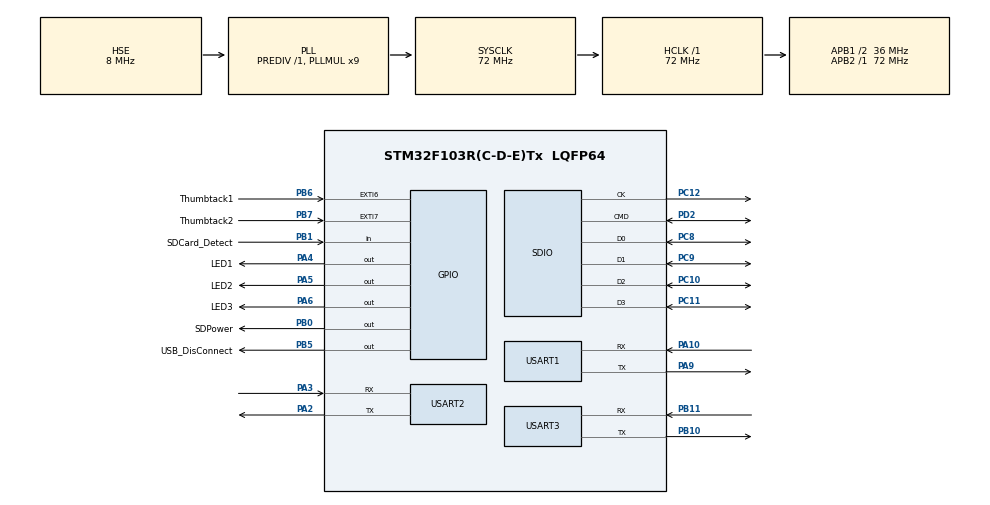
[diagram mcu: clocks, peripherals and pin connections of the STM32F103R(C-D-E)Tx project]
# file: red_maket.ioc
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FATFS._FS_NORTC=0
FATFS._STRF_ENCODE=0
FATFS._USE_MKFS=0
Mcu.Family=STM32F1
Mcu.Name=STM32F103R(C-D-E)Tx
Mcu.Package=LQFP64
NVIC.EXTI9_5_IRQn=true\:0\:0\:false\:false\:true\:true\:true\:true
NVIC.PriorityGroup=NVIC_PRIORITYGROUP_4
NVIC.USART1_IRQn=true\:0\:0\:false\:false\:true\:true\:true\:true
NVIC.USART2_IRQn=true\:0\:0\:false\:false\:true\:true\:true\:true
NVIC.USART3_IRQn=true\:0\:0\:false\:false\:true\:true\:true\:true
PA10.Mode=Asynchronous
PA10.Signal=USART1_RX
PA13.Mode=Trace_Asynchronous_SW
PA13.Signal=SYS_JTMS-SWDIO
PA14.Mode=Trace_Asynchronous_SW
PA14.Signal=SYS_JTCK-SWCLK
PA2.Mode=Asynchronous
PA2.Signal=USART2_TX
PA3.Mode=Asynchronous
PA3.Signal=USART2_RX
PA4.GPIO_Label=LED1
PA4.Signal=GPIO_Output
PA5.GPIO_Label=LED2
PA5.Signal=GPIO_Output
PA6.GPIO_Label=LED3
PA6.Signal=GPIO_Output
PA9.Mode=Asynchronous
PA9.Signal=USART1_TX
PB0.GPIO_Label=SDPower
PB0.Signal=GPIO_Output
PB1.GPIO_Label=SDCard_Detect
PB1.Signal=GPIO_Input
PB10.Mode=Asynchronous
PB10.Signal=USART3_TX
PB11.Mode=Asynchronous
PB11.Signal=USART3_RX
PB3.Mode=Trace_Asynchronous_SW
PB3.Signal=SYS_JTDO-TRACESWO
PB5.GPIO_Label=USB_DisConnect
PB5.Signal=GPIO_Output
PB6.GPIO_Label=Thumbtack1
PB6.Signal=GPXTI6
PB7.GPIO_Label=Thumbtack2
PB7.Signal=GPXTI7
PC10.Mode=SD_4_bits_Wide_bus
PC10.Signal=SDIO_D2
PC11.Mode=SD_4_bits_Wide_bus
PC11.Signal=SDIO_D3
PC12.Mode=SD_4_bits_Wide_bus
PC12.Signal=SDIO_CK
PC14-OSC32_IN.Mode=LSE-External-Oscillator
PC14-OSC32_IN.Signal=RCC_OSC32_IN
PC15-OSC32_OUT.Mode=LSE-External-Oscillator
PC15-OSC32_OUT.Signal=RCC_OSC32_OUT
PC8.Mode=SD_4_bits_Wide_bus
PC8.Signal=SDIO_D0
PC9.Mode=SD_4_bits_Wide_bus
PC9.Signal=SDIO_D1
PD0-OSC_IN.Mode=HSE-External-Oscillator
PD0-OSC_IN.Signal=RCC_OSC_IN
PD1-OSC_OUT.Mode=HSE-External-Oscillator
PD1-OSC_OUT.Signal=RCC_OSC_OUT
PD2.Mode=SD_4_bits_Wide_bus
PD2.Signal=SDIO_CMD
ProjectManager.HeapSize=0x200
ProjectManager.StackSize=0x400
ProjectManager.TargetToolchain=EWARM V8.32
RCC.AHBFreq_Value=72000000
RCC.APB1CLKDivider=RCC_HCLK_DIV2
RCC.APB1Freq_Value=36000000
RCC.APB1TimFreq_Value=72000000
RCC.APB2Freq_Value=72000000
RCC.APB2TimFreq_Value=72000000
RCC.EnbaleCSS=true
RCC.HCLKFreq_Value=72000000
RCC.PLLMUL=RCC_PLL_MUL9
RCC.PLLSourceVirtual=RCC_PLLSOURCE_HSE
RCC.RTCClockSelection=RCC_RTCCLKSOURCE_LSE
RCC.SYSCLKFreq_VALUE=72000000
RCC.SYSCLKSource=RCC_SYSCLKSOURCE_PLLCLK
RCC.USBFreq_Value=48000000
RCC.USBPrescaler=RCC_USBCLKSOURCE_PLL_DIV1_5
RTC.Date=1
RTC.Format=RTC_FORMAT_BIN
RTC.Month=RTC_MONTH_DECEMBER
RTC.WeekDay=RTC_WEEKDAY_MONDAY
RTC.Year=19
USART1.Parity=PARITY_EVEN
USART1.VirtualMode=VM_ASYNC
USART2.VirtualMode=VM_ASYNC
USART3.VirtualMode=VM_ASYNC
VP_FATFS_VS_SDIO.Mode=SDIO
VP_RTC_VS_RTC_Activate.Mode=RTC_Enabled
VP_RTC_VS_RTC_Calendar.Mode=RTC_Calendar
board=custom

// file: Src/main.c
/* USER CODE BEGIN Header */
/**
  ******************************************************************************
  * @file           : main.c
  * @brief          : Main program body
  ******************************************************************************
  * This notice applies to any and all portions of this file
  * that are not between comment pairs USER CODE BEGIN and
  * USER CODE END. Other portions of this file, whether
  * inserted by the user or by software development tools
  * are owned by their respective copyright owners.
  *
  * Copyright (c) 2019 STMicroelectronics International N.V.
  * All rights reserved.
  *
  * Redistribution and use in source and binary forms, with or without
  * modification, are permitted, provided that the following conditions are met:
  *
  * 1. Redistribution of source code must retain the above copyright notice,
  *    this list of conditions and the following disclaimer.
  * 2. Redistributions in binary form must reproduce the above copyright notice,
  *    this list of conditions and the following disclaimer in the documentation
  *    and/or other materials provided with the distribution.
  * 3. Neither the name of STMicroelectronics nor the names of other
  *    contributors to this software may be used to endorse or promote products
  *    derived from this software without specific written permission.
  * 4. This software, including modifications and/or derivative works of this
  *    software, must execute solely and exclusively on microcontroller or
  *    microprocessor devices manufactured by or for STMicroelectronics.
  * 5. Redistribution and use of this software other than as permitted under
  *    this license is void and will automatically terminate your rights under
  *    this license.
  *
  * THIS SOFTWARE IS PROVIDED BY STMICROELECTRONICS AND CONTRIBUTORS "AS IS"
  * AND ANY EXPRESS, IMPLIED OR STATUTORY WARRANTIES, INCLUDING, BUT NOT
  * LIMITED TO, THE IMPLIED WARRANTIES OF MERCHANTABILITY, FITNESS FOR A
  * PARTICULAR PURPOSE AND NON-INFRINGEMENT OF THIRD PARTY INTELLECTUAL PROPERTY
  * RIGHTS ARE DISCLAIMED TO THE FULLEST EXTENT PERMITTED BY LAW. IN NO EVENT
  * SHALL STMICROELECTRONICS OR CONTRIBUTORS BE LIABLE FOR ANY DIRECT, INDIRECT,
  * INCIDENTAL, SPECIAL, EXEMPLARY, OR CONSEQUENTIAL DAMAGES (INCLUDING, BUT NOT
  * LIMITED TO, PROCUREMENT OF SUBSTITUTE GOODS OR SERVICES; LOSS OF USE, DATA,
  * OR PROFITS; OR BUSINESS INTERRUPTION) HOWEVER CAUSED AND ON ANY THEORY OF
  * LIABILITY, WHETHER IN CONTRACT, STRICT LIABILITY, OR TORT (INCLUDING
  * NEGLIGENCE OR OTHERWISE) ARISING IN ANY WAY OUT OF THE USE OF THIS SOFTWARE,
  * EVEN IF ADVISED OF THE POSSIBILITY OF SUCH DAMAGE.
  *
  ******************************************************************************
  */
/* USER CODE END Header */
#include "main.h"
#include "fatfs.h"

 RTC_HandleTypeDef hrtc;

SD_HandleTypeDef hsd;

UART_HandleTypeDef huart1;
UART_HandleTypeDef huart2;
UART_HandleTypeDef huart3;

void SystemClock_Config(void);
static void MX_GPIO_Init(void);
static void MX_USART1_UART_Init(void);
static void MX_USART2_UART_Init(void);
static void MX_USART3_UART_Init(void);
static void MX_RTC_Init(void);
static void MX_SDIO_SD_Init(void);

int main(void)
{

  /* MCU Configuration--------------------------------------------------------*/

  /* Reset of all peripherals, Initializes the Flash interface and the Systick. */
  HAL_Init();

  /* Configure the system clock */
  SystemClock_Config();

  /* Initialize all configured peripherals */
  MX_GPIO_Init();
  MX_USART1_UART_Init();
  MX_USART2_UART_Init();
  MX_USART3_UART_Init();
  MX_RTC_Init();
  MX_SDIO_SD_Init();
  MX_FATFS_Init();

  /* Infinite loop */
  /* USER CODE BEGIN WHILE */
  while(1)
  {
	char	 	tmp[256];
	tmp[0] = 1;
	tmp[1] = 2;
	tmp[2] = 3;
	tmp[3] = 4;
	tmp[4] = 5;
	tmp[5] = 6;
	tmp[6] = 7;
	tmp[7] = 8;
	tmp[8] = 9;
	tmp[9] = 10;

	HAL_UART_Transmit(&huart1, (uint8_t *)&tmp, 10, 5000);

	HAL_UART_Receive(&huart1, (uint8_t *)&tmp, 1, 5000);

	HAL_GPIO_TogglePin(LED2_GPIO_Port, LED2_Pin);

    /* USER CODE END WHILE */

  }
}

void SystemClock_Config(void)
{
  RCC_OscInitTypeDef RCC_OscInitStruct = {0};
  RCC_ClkInitTypeDef RCC_ClkInitStruct = {0};
  RCC_PeriphCLKInitTypeDef PeriphClkInit = {0};

  /** Initializes the RCC Oscillators according to the specified parameters
  * in the RCC_OscInitTypeDef structure.
  */
  RCC_OscInitStruct.OscillatorType = RCC_OSCILLATORTYPE_HSE|RCC_OSCILLATORTYPE_LSE;
  RCC_OscInitStruct.HSEState = RCC_HSE_ON;
  RCC_OscInitStruct.HSEPredivValue = RCC_HSE_PREDIV_DIV1;
  RCC_OscInitStruct.LSEState = RCC_LSE_ON;
  RCC_OscInitStruct.HSIState = RCC_HSI_ON;
  RCC_OscInitStruct.PLL.PLLState = RCC_PLL_ON;
  RCC_OscInitStruct.PLL.PLLSource = RCC_PLLSOURCE_HSE;
  RCC_OscInitStruct.PLL.PLLMUL = RCC_PLL_MUL9;
  if (HAL_RCC_OscConfig(&RCC_OscInitStruct) != HAL_OK)
  {
    Error_Handler();
  }

  /** Initializes the CPU, AHB and APB buses clocks
  */
  RCC_ClkInitStruct.ClockType = RCC_CLOCKTYPE_HCLK|RCC_CLOCKTYPE_SYSCLK
                              |RCC_CLOCKTYPE_PCLK1|RCC_CLOCKTYPE_PCLK2;
  RCC_ClkInitStruct.SYSCLKSource = RCC_SYSCLKSOURCE_PLLCLK;
  RCC_ClkInitStruct.AHBCLKDivider = RCC_SYSCLK_DIV1;
  RCC_ClkInitStruct.APB1CLKDivider = RCC_HCLK_DIV2;
  RCC_ClkInitStruct.APB2CLKDivider = RCC_HCLK_DIV1;

  if (HAL_RCC_ClockConfig(&RCC_ClkInitStruct, FLASH_LATENCY_2) != HAL_OK)
  {
    Error_Handler();
  }
  PeriphClkInit.PeriphClockSelection = RCC_PERIPHCLK_RTC;
  PeriphClkInit.RTCClockSelection = RCC_RTCCLKSOURCE_LSE;
  if (HAL_RCCEx_PeriphCLKConfig(&PeriphClkInit) != HAL_OK)
  {
    Error_Handler();
  }

  /** Enables the Clock Security System
  */
  HAL_RCC_EnableCSS();
}

static void MX_RTC_Init(void)
{

  RTC_TimeTypeDef sTime = {0};
  RTC_DateTypeDef DateToUpdate = {0};

  /** Initialize RTC Only
  */
  hrtc.Instance = RTC;
  hrtc.Init.AsynchPrediv = RTC_AUTO_1_SECOND;
  hrtc.Init.OutPut = RTC_OUTPUTSOURCE_ALARM;
  if (HAL_RTC_Init(&hrtc) != HAL_OK)
  {
    Error_Handler();
  }

  /** Initialize RTC and set the Time and Date
  */
  sTime.Hours = 0;
  sTime.Minutes = 0;
  sTime.Seconds = 0;

  if (HAL_RTC_SetTime(&hrtc, &sTime, RTC_FORMAT_BIN) != HAL_OK)
  {
    Error_Handler();
  }
  DateToUpdate.WeekDay = RTC_WEEKDAY_MONDAY;
  DateToUpdate.Month = RTC_MONTH_DECEMBER;
  DateToUpdate.Date = 1;
  DateToUpdate.Year = 19;

  if (HAL_RTC_SetDate(&hrtc, &DateToUpdate, RTC_FORMAT_BIN) != HAL_OK)
  {
    Error_Handler();
  }

}

static void MX_SDIO_SD_Init(void)
{

  hsd.Instance = SDIO;
  hsd.Init.ClockEdge = SDIO_CLOCK_EDGE_RISING;
  hsd.Init.ClockBypass = SDIO_CLOCK_BYPASS_DISABLE;
  hsd.Init.ClockPowerSave = SDIO_CLOCK_POWER_SAVE_DISABLE;
  hsd.Init.BusWide = SDIO_BUS_WIDE_1B;
  hsd.Init.HardwareFlowControl = SDIO_HARDWARE_FLOW_CONTROL_DISABLE;
  hsd.Init.ClockDiv = 0;

}

static void MX_USART1_UART_Init(void)
{

  huart1.Instance = USART1;
  huart1.Init.BaudRate = 115200;
  huart1.Init.WordLength = UART_WORDLENGTH_8B;
  huart1.Init.StopBits = UART_STOPBITS_1;
  huart1.Init.Parity = UART_PARITY_EVEN;
  huart1.Init.Mode = UART_MODE_TX_RX;
  huart1.Init.HwFlowCtl = UART_HWCONTROL_NONE;
  huart1.Init.OverSampling = UART_OVERSAMPLING_16;
  if (HAL_UART_Init(&huart1) != HAL_OK)
  {
    Error_Handler();
  }

}

static void MX_USART2_UART_Init(void)
{

  huart2.Instance = USART2;
  huart2.Init.BaudRate = 115200;
  huart2.Init.WordLength = UART_WORDLENGTH_8B;
  huart2.Init.StopBits = UART_STOPBITS_1;
  huart2.Init.Parity = UART_PARITY_NONE;
  huart2.Init.Mode = UART_MODE_TX_RX;
  huart2.Init.HwFlowCtl = UART_HWCONTROL_NONE;
  huart2.Init.OverSampling = UART_OVERSAMPLING_16;
  if (HAL_UART_Init(&huart2) != HAL_OK)
  {
    Error_Handler();
  }

}

static void MX_USART3_UART_Init(void)
{

  huart3.Instance = USART3;
  huart3.Init.BaudRate = 115200;
  huart3.Init.WordLength = UART_WORDLENGTH_8B;
  huart3.Init.StopBits = UART_STOPBITS_1;
  huart3.Init.Parity = UART_PARITY_NONE;
  huart3.Init.Mode = UART_MODE_TX_RX;
  huart3.Init.HwFlowCtl = UART_HWCONTROL_NONE;
  huart3.Init.OverSampling = UART_OVERSAMPLING_16;
  if (HAL_UART_Init(&huart3) != HAL_OK)
  {
    Error_Handler();
  }

}

static void MX_GPIO_Init(void)
{
  GPIO_InitTypeDef GPIO_InitStruct = {0};

  /* GPIO Ports Clock Enable */
  __HAL_RCC_GPIOC_CLK_ENABLE();
  __HAL_RCC_GPIOD_CLK_ENABLE();
  __HAL_RCC_GPIOA_CLK_ENABLE();
  __HAL_RCC_GPIOB_CLK_ENABLE();

  /*Configure GPIO pin Output Level */
  HAL_GPIO_WritePin(GPIOA, LED1_Pin|LED2_Pin|LED3_Pin, GPIO_PIN_RESET);

  /*Configure GPIO pin Output Level */
  HAL_GPIO_WritePin(GPIOB, SDPower_Pin|USB_DisConnect_Pin, GPIO_PIN_RESET);

  /*Configure GPIO pins : LED1_Pin LED2_Pin LED3_Pin */
  GPIO_InitStruct.Pin = LED1_Pin|LED2_Pin|LED3_Pin;
  GPIO_InitStruct.Mode = GPIO_MODE_OUTPUT_PP;
  GPIO_InitStruct.Pull = GPIO_NOPULL;
  GPIO_InitStruct.Speed = GPIO_SPEED_FREQ_LOW;
  HAL_GPIO_Init(GPIOA, &GPIO_InitStruct);

  /*Configure GPIO pins : SDPower_Pin USB_DisConnect_Pin */
  GPIO_InitStruct.Pin = SDPower_Pin|USB_DisConnect_Pin;
  GPIO_InitStruct.Mode = GPIO_MODE_OUTPUT_PP;
  GPIO_InitStruct.Pull = GPIO_NOPULL;
  GPIO_InitStruct.Speed = GPIO_SPEED_FREQ_LOW;
  HAL_GPIO_Init(GPIOB, &GPIO_InitStruct);

  /*Configure GPIO pin : SDCard_Detect_Pin */
  GPIO_InitStruct.Pin = SDCard_Detect_Pin;
  GPIO_InitStruct.Mode = GPIO_MODE_INPUT;
  GPIO_InitStruct.Pull = GPIO_NOPULL;
  HAL_GPIO_Init(SDCard_Detect_GPIO_Port, &GPIO_InitStruct);

  /*Configure GPIO pins : Thumbtack1_Pin Thumbtack2_Pin */
  GPIO_InitStruct.Pin = Thumbtack1_Pin|Thumbtack2_Pin;
  GPIO_InitStruct.Mode = GPIO_MODE_IT_RISING;
  GPIO_InitStruct.Pull = GPIO_NOPULL;
  HAL_GPIO_Init(GPIOB, &GPIO_InitStruct);

  /* EXTI interrupt init*/
  HAL_NVIC_SetPriority(EXTI9_5_IRQn, 0, 0);
  HAL_NVIC_EnableIRQ(EXTI9_5_IRQn);

}

void Error_Handler(void)
{
}
